# STM32WB50_CM4 register map
File version: 1.7
CPU: CM4 r0p1, little endian, MPU, FPU, 4 interrupt priority bits
Registers are 32-bit, read-write, reset 0x0 unless marked. A register's access mark holds for its fields unless they carry their own. Offsets are from the block's base; [hi:lo] are bit positions; {n}, {i} and the like mark numbered series.

## IPCC
Base 0x58000C00
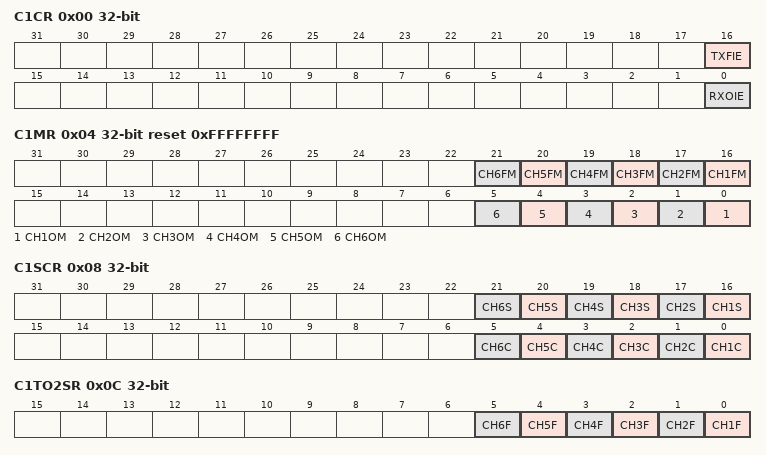
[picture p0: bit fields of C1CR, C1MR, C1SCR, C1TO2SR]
0x00 C1CR — Control register CPU1
  [16] TXFIE — processor 1 Transmit channel free interrupt enable
  [0] RXOIE — processor 1 Receive channel occupied interrupt enable
0x04 C1MR reset 0xFFFFFFFF — Mask register CPU1
  [n+15] CH{n}FM (n=1..6) — processor 1 Transmit channel {n} free interrupt mask
  [n-1] CH{n}OM (n=1..6) — processor 1 Receive channel {n} occupied interrupt enable
0x08 C1SCR wo — Status Set or Clear register CPU1
  [n+15] CH{n}S (n=1..6) — processor 1 Transmit channel {n} status set
  [n-1] CH{n}C (n=1..6) — processor 1 Receive channel {n} status clear
0x0C C1TO2SR ro — CPU1 to CPU2 status register
  [n-1] CH{n}F (n=1..6) — processor 1 transmit to process 2 Receive channel {n} status flag
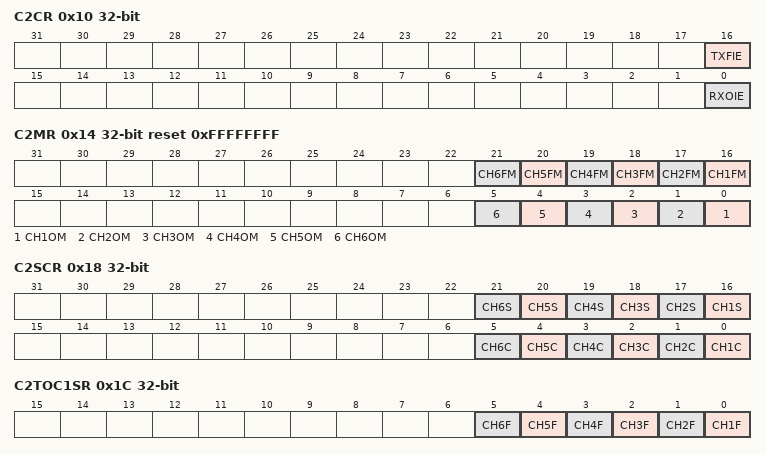
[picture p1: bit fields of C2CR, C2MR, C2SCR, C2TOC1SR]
0x10 C2CR — Control register CPU2
  [16] TXFIE — processor 2 Transmit channel free interrupt enable
  [0] RXOIE — processor 2 Receive channel occupied interrupt enable
0x14 C2MR reset 0xFFFFFFFF — Mask register CPU2
  [n+15] CH{n}FM (n=1..6) — processor 2 Transmit channel {n} free interrupt mask
  [n-1] CH{n}OM (n=1..6) — processor 2 Receive channel {n} occupied interrupt enable
0x18 C2SCR wo — Status Set or Clear register CPU2
  [n+15] CH{n}S (n=1..6) — processor 2 Transmit channel {n} status set
  [n-1] CH{n}C (n=1..6) — processor 2 Receive channel {n} status clear
0x1C C2TOC1SR ro — CPU2 to CPU1 status register
  [n-1] CH{n}F (n=1..6) — processor 2 transmit to process 1 Receive channel {n} status flag
0x3F0 HWCFGR ro reset 0x6 — IPCC Hardware configuration register
  [7:0] CHANNELS — Number of channels per CPU supported by the IP, range 1 to 16
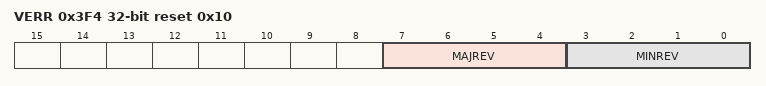
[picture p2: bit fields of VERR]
0x3F4 VERR ro reset 0x10 — IPCC version register
  [7:4] MAJREV — Major Revision
  [3:0] MINREV — Minor Revision
0x3F8 IPIDR ro reset 0x100071 — IPCC indentification register
  [31:0] IPID — Identification Code
0x3FC SIDR ro reset 0xA3C5DD01 — IPCC size indentification register
  [31:0] SID — Size Identification Code

## IWDG — Independent watchdog
Base 0x40003000
0x00 KR wo — Key register
  [15:0] KEY — Key value (write only, read 0x0000)
0x04 PR — Prescaler register
  [2:0] PR — Prescaler divider
0x08 RLR reset 0xFFF — Reload register
  [11:0] RL — Watchdog counter reload value
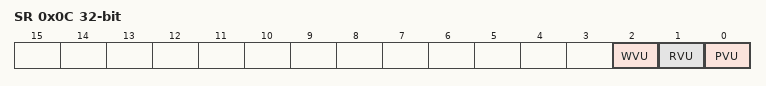
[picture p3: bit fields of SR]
0x0C SR ro — Status register
  [2] WVU — Watchdog counter window value update
  [1] RVU — Watchdog counter reload value update
  [0] PVU — Watchdog prescaler value update
0x10 WINR reset 0xFFF — Window register
  [11:0] WIN — Watchdog counter window value

## LPTIM1 — Low power timer
Base 0x40007C00
Same registers: LPTIM2 0x40009400
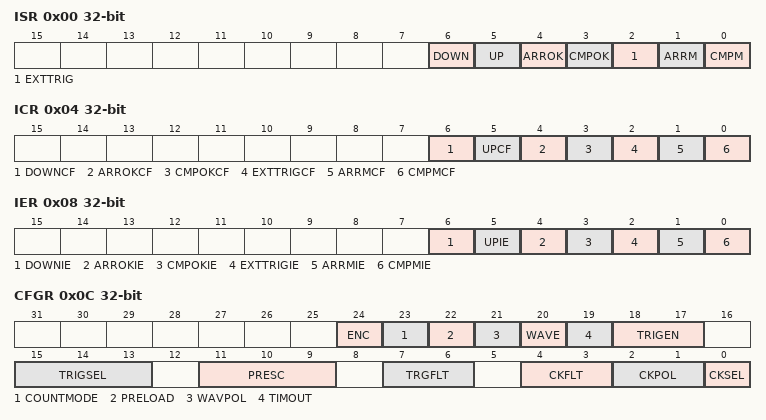
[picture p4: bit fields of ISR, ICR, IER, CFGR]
0x00 ISR ro — Interrupt and Status Register
  [6] DOWN — Counter direction change up to down
  [5] UP — Counter direction change down to up
  [4] ARROK — Autoreload register update OK
  [3] CMPOK — Compare register update OK
  [2] EXTTRIG — External trigger edge event
  [1] ARRM — Autoreload match
  [0] CMPM — Compare match
0x04 ICR wo — Interrupt Clear Register
  [6] DOWNCF — Direction change to down Clear Flag
  [5] UPCF — Direction change to UP Clear Flag
  [4] ARROKCF — Autoreload register update OK Clear Flag
  [3] CMPOKCF — Compare register update OK Clear Flag
  [2] EXTTRIGCF — External trigger valid edge Clear Flag
  [1] ARRMCF — Autoreload match Clear Flag
  [0] CMPMCF — compare match Clear Flag
0x08 IER — Interrupt Enable Register
  [6] DOWNIE — Direction change to down Interrupt Enable
  [5] UPIE — Direction change to UP Interrupt Enable
  [4] ARROKIE — Autoreload register update OK Interrupt Enable
  [3] CMPOKIE — Compare register update OK Interrupt Enable
  [2] EXTTRIGIE — External trigger valid edge Interrupt Enable
  [1] ARRMIE — Autoreload match Interrupt Enable
  [0] CMPMIE — Compare match Interrupt Enable
0x0C CFGR — Configuration Register
  [24] ENC — Encoder mode enable
  [23] COUNTMODE — counter mode enabled
  [22] PRELOAD — Registers update mode
  [21] WAVPOL — Waveform shape polarity
  [20] WAVE — Waveform shape
  [19] TIMOUT — Timeout enable
  [18:17] TRIGEN — Trigger enable and polarity
  [15:13] TRIGSEL — Trigger selector
  [11:9] PRESC — Clock prescaler
  [7:6] TRGFLT — Configurable digital filter for trigger
  [4:3] CKFLT — Configurable digital filter for external clock
  [2:1] CKPOL — Clock Polarity
  [0] CKSEL — Clock selector
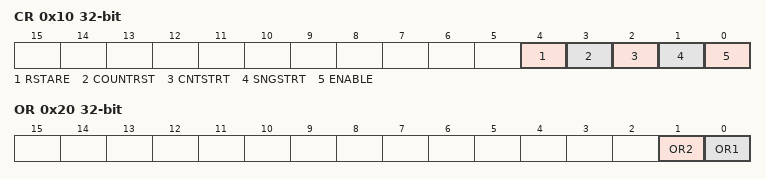
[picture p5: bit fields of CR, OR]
0x10 CR — Control Register
  [4] RSTARE — Reset after read enable
  [3] COUNTRST — Counter reset
  [2] CNTSTRT — Timer start in continuous mode
  [1] SNGSTRT — LPTIM start in single mode
  [0] ENABLE — LPTIM Enable
0x14 CMP — Compare Register
  [15:0] CMP — Compare value
0x18 ARR reset 0x1 — Autoreload Register
  [15:0] ARR — Auto reload value
0x1C CNT ro — Counter Register
  [15:0] CNT — Counter value
0x20 OR — Option Register
  [1] OR2 — Option register bit 2
  [0] OR1 — Option register bit 1
